/*
 * The MIT License (MIT)
 *
 * Copyright (c) 2015-2019 Erik Moqvist
 *
 * Permission is hereby granted, free of charge, to any person obtaining a copy
 * of this software and associated documentation files (the "Software"), to deal
 * in the Software without restriction, including without limitation the rights
 * to use, copy, modify, merge, publish, distribute, sublicense, and/or sell
 * copies of the Software, and to permit persons to whom the Software is
 * furnished to do so, subject to the following conditions:
 *
 * The above copyright notice and this permission notice shall be included in all
 * copies or substantial portions of the Software.
 *
 * THE SOFTWARE IS PROVIDED "AS IS", WITHOUT WARRANTY OF ANY KIND, EXPRESS OR
 * IMPLIED, INCLUDING BUT NOT LIMITED TO THE WARRANTIES OF MERCHANTABILITY,
 * FITNESS FOR A PARTICULAR PURPOSE AND NONINFRINGEMENT. IN NO EVENT SHALL THE
 * AUTHORS OR COPYRIGHT HOLDERS BE LIABLE FOR ANY CLAIM, DAMAGES OR OTHER
 * LIABILITY, WHETHER IN AN ACTION OF CONTRACT, TORT OR OTHERWISE, ARISING FROM,
 * OUT OF OR IN CONNECTION WITH THE SOFTWARE OR THE USE OR OTHER DEALINGS IN THE
 * SOFTWARE.
 */

VERSION "1.0"

NS_ :

BS_:

BU_: PCM1 FOO

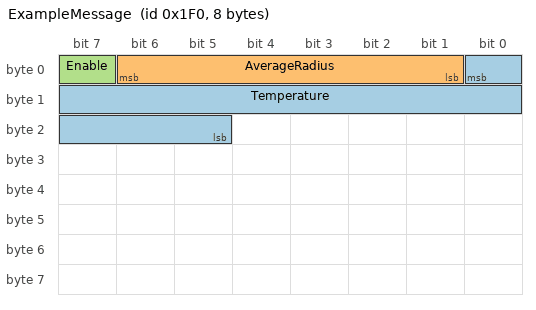
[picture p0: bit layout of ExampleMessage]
BO_ 496 ExampleMessage: 8 PCM1
 SG_ Temperature : 0|12@0- (0.01,250) [229.52|270.47] "degK"  PCM1,FOO
 SG_ AverageRadius : 6|6@0+ (0.1,0) [0|5] "m" Vector__XXX
 SG_ Enable : 7|1@0+ (1,0) [0|0] "-" Vector__XXX

CM_ BO_ 496 "Example message used as template in MotoHawk models.";
CM_ SG_ 496 Temperature "Temperature with a really long and complicated comment that probably require many many lines in a decently wide terminal";
CM_ SG_ 496 AverageRadius "AverageRadius signal comment";
CM_ SG_ 496 Enable "Enable signal comment";

VAL_ 496 Enable 0 "Disabled" 1 "Enabled" ;
